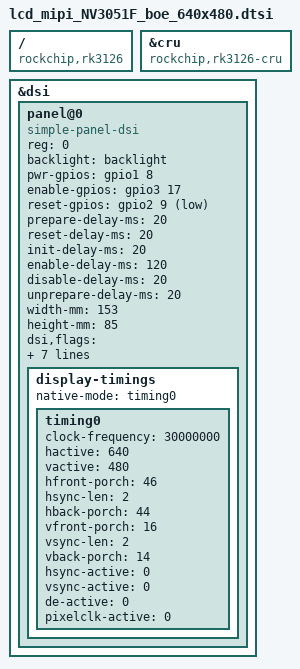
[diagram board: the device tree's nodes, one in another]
/*
 * This file is dual-licensed: you can use it either under the terms
 * of the GPL or the X11 license, at your option. Note that this dual
 * licensing only applies to this file, and not this project as a
 * whole.
 *
 *  a) This file is free software; you can redistribute it and/or
 *     modify it under the terms of the GNU General Public License as
 *     published by the Free Software Foundation; either version 2 of the
 *     License, or (at your option) any later version.
 *
 *     This file is distributed in the hope that it will be useful,
 *     but WITHOUT ANY WARRANTY; without even the implied warranty of
 *     MERCHANTABILITY or FITNESS FOR A PARTICULAR PURPOSE.  See the
 *     GNU General Public License for more details.
 *
 * Or, alternatively,
 *
 *  b) Permission is hereby granted, free of charge, to any person
 *     obtaining a copy of this software and associated documentation
 *     files (the "Software"), to deal in the Software without
 *     restriction, including without limitation the rights to use,
 *     copy, modify, merge, publish, distribute, sublicense, and/or
 *     sell copies of the Software, and to permit persons to whom the
 *     Software is furnished to do so, subject to the following
 *     conditions:
 *
 *     The above copyright notice and this permission notice shall be
 *     included in all copies or substantial portions of the Software.
 *
 *     THE SOFTWARE IS PROVIDED "AS IS", WITHOUT WARRANTY OF ANY KIND,
 *     EXPRESS OR IMPLIED, INCLUDING BUT NOT LIMITED TO THE WARRANTIES
 *     OF MERCHANTABILITY, FITNESS FOR A PARTICULAR PURPOSE AND
 *     NONINFRINGEMENT. IN NO EVENT SHALL THE AUTHORS OR COPYRIGHT
 *     HOLDERS BE LIABLE FOR ANY CLAIM, DAMAGES OR OTHER LIABILITY,
 *     WHETHER IN AN ACTION OF CONTRACT, TORT OR OTHERWISE, ARISING
 *     FROM, OUT OF OR IN CONNECTION WITH THE SOFTWARE OR THE USE OR
 *     OTHER DEALINGS IN THE SOFTWARE.
 */

#include "../rk312x.dtsi"
#include <dt-bindings/display/drm_mipi_dsi.h>

/ {
	compatible = "rockchip,rk3126";
};

&cru {
	compatible = "rockchip,rk3126-cru";
};

&dsi {
	status = "okay";

	panel@0 {
		compatible = "simple-panel-dsi";
		reg = <0>;
		backlight = <&backlight>;
		pwr-gpios = <&gpio1 8 GPIO_ACTIVE_HIGH>;
        	enable-gpios = <&gpio3 17 GPIO_ACTIVE_HIGH>;
		reset-gpios = <&gpio2 9 GPIO_ACTIVE_LOW>;
		prepare-delay-ms = <20>;
		reset-delay-ms = <20>;
		init-delay-ms = <20>;
		enable-delay-ms = <120>;
		disable-delay-ms = <20>;
		unprepare-delay-ms = <20>;

		width-mm = <153>;
		height-mm = <85>;
		
		dsi,flags = <(MIPI_DSI_MODE_VIDEO | MIPI_DSI_MODE_VIDEO_BURST |
			      MIPI_DSI_MODE_LPM | MIPI_DSI_MODE_EOT_PACKET)>;
		dsi,format = <MIPI_DSI_FMT_RGB888>;

		dsi,lanes = <4>;

		panel-init-sequence = [
		    15 00 02 FF 30
		    15 00 02 FF 52
			15 00 02 FF 01
			15 00 02 E3 00
			15 00 02 25 10
			15 00 02 28 6F
			15 00 02 29 01
			15 00 02 2A df
			15 00 02 2C 22
			15 00 02 C3 0F
			15 00 02 37 9C
			15 00 02 38 A7
			15 00 02 39 41
			15 00 02 80 20
			15 00 02 91 67
			15 00 02 92 67
			15 00 02 A0 55
			15 00 02 A1 50
			15 00 02 A3 58
			15 00 02 A4 9C
			15 00 02 A7 02
			15 00 02 A8 01
			15 00 02 A9 21
			15 00 02 AA FC
			15 00 02 AB 28
			15 00 02 AC 06
			15 00 02 AD 06
			15 00 02 AE 06
			15 00 02 AF 03
			15 00 02 B0 08
			15 00 02 B1 26
			15 00 02 B2 28
			15 00 02 B3 28
			15 00 02 B4 03
			15 00 02 B5 08
			15 00 02 B6 26
			15 00 02 B7 08
			15 00 02 B8 26
			15 00 02 C0 00
			15 00 02 C1 00
			15 00 02 C2 00
			15 00 02 FF 30
			15 00 02 FF 52
			15 00 02 FF 02
			15 00 02 B0 02
			15 00 02 D0 02
			15 00 02 B1 0f
			15 00 02 D1 10
			15 00 02 B2 11
			15 00 02 D2 12
			15 00 02 B3 32
			15 00 02 D3 33
			15 00 02 B4 36
			15 00 02 D4 36
			15 00 02 B5 3C
			15 00 02 D5 3C
			15 00 02 B6 20
			15 00 02 D6 20
			15 00 02 B7 3e
			15 00 02 D7 3e
			15 00 02 B8 0E
			15 00 02 D8 0d
			15 00 02 B9 05
			15 00 02 D9 05
			15 00 02 BA 11
			15 00 02 DA 12
			15 00 02 BB 11
			15 00 02 DB 11
			15 00 02 BC 13
			15 00 02 DC 14
			15 00 02 BD 14
			15 00 02 DD 14
			15 00 02 BE 16
			15 00 02 DE 18
			15 00 02 BF 0e
			15 00 02 DF 0f
			15 00 02 C0 17
			15 00 02 E0 17
			15 00 02 C1 07
			15 00 02 E1 08
			15 00 02 FF 30
			15 00 02 FF 52
			15 00 02 FF 03
			15 00 02 08 8A
			15 00 02 09 8B
			15 00 02 30 00
			15 00 02 31 00
			15 00 02 32 00
			15 00 02 33 00
			15 00 02 34 61
			15 00 02 35 D4
			15 00 02 36 24
			15 00 02 37 03
			15 00 02 40 86
			15 00 02 41 87
			15 00 02 42 84
			15 00 02 43 85
			15 00 02 44 11
			15 00 02 45 DE
			15 00 02 46 DD
			15 00 02 47 11
			15 00 02 48 E0
			15 00 02 49 DF
			15 00 02 50 82
			15 00 02 51 83
			15 00 02 52 80
			15 00 02 53 81
			15 00 02 54 11
			15 00 02 55 E2
			15 00 02 56 E1
			15 00 02 57 11
			15 00 02 58 E4
			15 00 02 59 E3
			15 00 02 82 0F
			15 00 02 83 0F
			15 00 02 84 00
			15 00 02 85 0F
			15 00 02 86 0F
			15 00 02 87 0E
			15 00 02 88 0E
			15 00 02 89 06
			15 00 02 8A 06
			15 00 02 8B 07
			15 00 02 8C 07
			15 00 02 8D 04
			15 00 02 8E 04
			15 00 02 8F 05
			15 00 02 90 05
			15 00 02 98 0F
			15 00 02 99 0F
			15 00 02 9A 00
			15 00 02 9B 0F
			15 00 02 9C 0F
			15 00 02 9D 0E
			15 00 02 9E 0E
			15 00 02 9F 06
			15 00 02 A0 06
			15 00 02 A1 07
			15 00 02 A2 07
			15 00 02 A3 04
			15 00 02 A4 04
			15 00 02 A5 05
			15 00 02 A6 05
			15 00 02 E0 02
			15 00 02 E1 52
			15 00 02 FF 30
			15 00 02 FF 52
			15 00 02 FF 00
			15 00 02 36 02
			05 c8 01 11 
			05 64 01 29
		];

		panel-exit-sequence = [
			05 00 01 28
			05 00 01 10
		];

		display-timings {
			native-mode = <&timing0>;

			timing0: timing0 {
				clock-frequency = <30000000>;
				hactive = <640>;
				vactive = <480>;
				hfront-porch = <46>;
				hsync-len = <2>;
				hback-porch = <44>;
				vfront-porch = <16>;
				vsync-len = <2>;
				vback-porch = <14>;
				hsync-active = <0>;
				vsync-active = <0>;
				de-active = <0>;
				pixelclk-active = <0>;
			};
		};
	};
};
